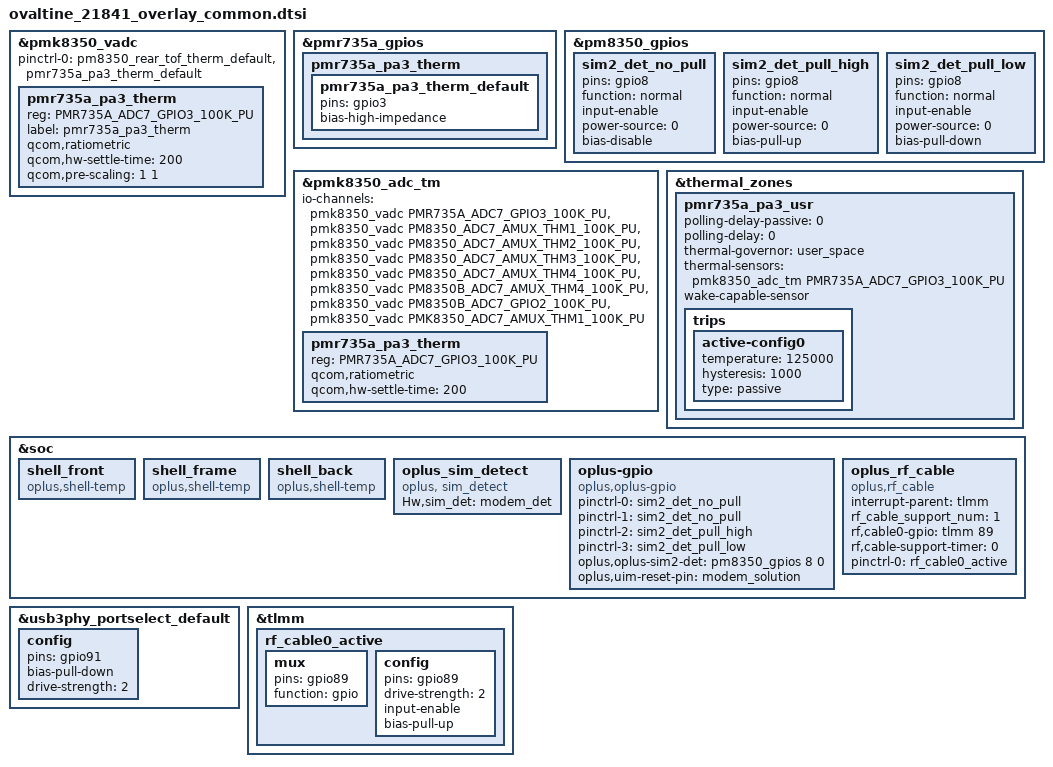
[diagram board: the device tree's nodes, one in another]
#include "tp/ovaltine_21841_extra_config.dtsi"

&pmk8350_vadc {
	pinctrl-names = "default";
	pinctrl-0 = <&pm8350_rear_tof_therm_default &pmr735a_pa3_therm_default>;

	/delete-node/ pm8350_rear_tof_therm;

	pmr735a_pa3_therm {
		reg = <PMR735A_ADC7_GPIO3_100K_PU>;
		label = "pmr735a_pa3_therm";
		qcom,ratiometric;
		qcom,hw-settle-time = <200>;
		qcom,pre-scaling = <1 1>;
	};
};

&pmr735a_gpios {
	pmr735a_pa3_therm {
         pmr735a_pa3_therm_default: pmr735a_pa3_therm_default {
               pins = "gpio3";
               bias-high-impedance;
         };
      };
};

&pm8350_gpios {
	//#ifdef OPLUS_FEATRUE_DUAL_SIM_DETECT
	sim2_det_no_pull: sim2_det_no_pull {
			pins = "gpio8";
			function = "normal";
			input-enable;
			power-source = <0>;
			bias-disable;
	};

	sim2_det_pull_high: sim2_det_pull_high {
			pins = "gpio8";
			function = "normal";
			input-enable;
			power-source = <0>;
			bias-pull-up;
	};

	sim2_det_pull_low: sim2_det_pull_low {
			pins = "gpio8";
			function = "normal";
			input-enable;
			power-source = <0>;
			bias-pull-down;
	};
	//#endif OPLUS_FEATRUE_DUAL_SIM_DETECT
};

&pmk8350_adc_tm {
	io-channels = <&pmk8350_vadc PMR735A_ADC7_GPIO3_100K_PU>,
			<&pmk8350_vadc PM8350_ADC7_AMUX_THM1_100K_PU>,
			<&pmk8350_vadc PM8350_ADC7_AMUX_THM2_100K_PU>,
			<&pmk8350_vadc PM8350_ADC7_AMUX_THM3_100K_PU>,
			<&pmk8350_vadc PM8350_ADC7_AMUX_THM4_100K_PU>,
//			<&pmk8350_vadc PM8350_ADC7_AMUX_THM5_100K_PU>,
			<&pmk8350_vadc PM8350B_ADC7_AMUX_THM4_100K_PU>,
			<&pmk8350_vadc PM8350B_ADC7_GPIO2_100K_PU>,
			<&pmk8350_vadc PMK8350_ADC7_AMUX_THM1_100K_PU>;

	/delete-node/ pm8350_rear_tof_therm;

	pmr735a_pa3_therm {
		reg = <PMR735A_ADC7_GPIO3_100K_PU>;
		qcom,ratiometric;
		qcom,hw-settle-time = <200>;
	};
};

&thermal_zones {

	/delete-node/ pm8350_rear_tof_therm;

	pmr735a_pa3_usr {
		polling-delay-passive = <0>;
		polling-delay = <0>;
		thermal-governor = "user_space";
		thermal-sensors = <&pmk8350_adc_tm PMR735A_ADC7_GPIO3_100K_PU>;
		wake-capable-sensor;
		trips {
			active-config0 {
				temperature = <125000>;
				hysteresis = <1000>;
				type = "passive";
			};
		};
	};
};

//#ifdef OPLUS_FEATURE_THERMAL_HORAE
&soc {
	shell_front {
			compatible = "oplus,shell-temp";
	};

	shell_frame {
			compatible = "oplus,shell-temp";
	};

	shell_back {
			compatible = "oplus,shell-temp";
	};
//#endif OPLUS_FEATURE_THERMAL_HORAE
};

//Add to change cc-out gpio pull down
&usb3phy_portselect_default {
	config {
		pins = "gpio91";
		bias-pull-down;
		drive-strength = <2>;
	};
};

&soc {
	//#ifdef OPLUS_FEATRUE_SIM_HOLDER_DETECT
	oplus_sim_detect {
		compatible = "oplus, sim_detect";
		Hw,sim_det = "modem_det";
	};
	//#endif /* OPLUS_FEATRUE_SIM_HOLDER_DETECT */

	//#ifdef OPLUS_FEATRUE_DUAL_SIM_DETECT
	oplus-gpio {
		compatible = "oplus,oplus-gpio";
		pinctrl-names = "default", "sim2_det_no_pull", "sim2_det_pull_high", "sim2_det_pull_low";
		pinctrl-0 = <&sim2_det_no_pull>;
		pinctrl-1 = <&sim2_det_no_pull>;
		pinctrl-2 = <&sim2_det_pull_high>;
		pinctrl-3 = <&sim2_det_pull_low>;
		oplus,oplus-sim2-det = <&pm8350_gpios 8 0>;
		oplus,uim-reset-pin = "modem_solution";
	};
	//#endif /* OPLUS_FEATRUE_DUAL_SIM_DETECT */
};

&tlmm {
  rf_cable0_active: rf_cable0_active {
    mux {
      pins = "gpio89";
      function = "gpio";
    };
    config {
      pins = "gpio89";
      drive-strength = <2>;
      input-enable;
      bias-pull-up;
    };
  };
};

&soc {
  oplus_rf_cable {
    compatible = "oplus,rf_cable";
    interrupt-parent = <&tlmm>;
    rf_cable_support_num = <1>;
    rf,cable0-gpio = <&tlmm 89 0>;
    rf,cable-support-timer = <0>;
    pinctrl-names = "rf_cable_active";
    pinctrl-0 = <&rf_cable0_active>;
  };
};
